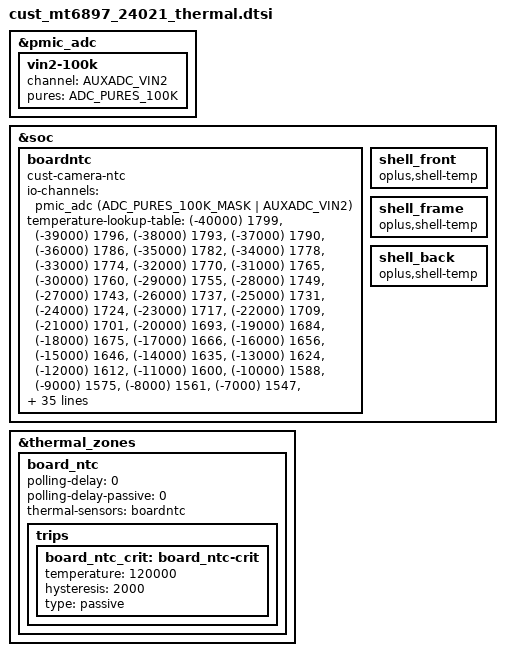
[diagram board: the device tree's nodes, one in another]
// SPDX-License-Identifier: GPL-2.0-only
/*
* Copyright (C) 2022 Oplus. All rights reserved.
*/

#include <dt-bindings/iio/mt635x-auxadc.h>

&pmic_adc {
	vin2-100k {
		channel = <AUXADC_VIN2>;
		pures = <ADC_PURES_100K>;
	};
};

&soc {
	boardntc: boardntc {
		compatible = "cust-camera-ntc";
		#thermal-sensor-cells = <0>;
		io-channels = <&pmic_adc (ADC_PURES_100K_MASK | AUXADC_VIN2)>;
		io-channel-names = "sensor-channel";
		temperature-lookup-table =
			<(-40000) 1799>,
			<(-39000) 1796>,
			<(-38000) 1793>,
			<(-37000) 1790>,
			<(-36000) 1786>,
			<(-35000) 1782>,
			<(-34000) 1778>,
			<(-33000) 1774>,
			<(-32000) 1770>,
			<(-31000) 1765>,
			<(-30000) 1760>,
			<(-29000) 1755>,
			<(-28000) 1749>,
			<(-27000) 1743>,
			<(-26000) 1737>,
			<(-25000) 1731>,
			<(-24000) 1724>,
			<(-23000) 1717>,
			<(-22000) 1709>,
			<(-21000) 1701>,
			<(-20000) 1693>,
			<(-19000) 1684>,
			<(-18000) 1675>,
			<(-17000) 1666>,
			<(-16000) 1656>,
			<(-15000) 1646>,
			<(-14000) 1635>,
			<(-13000) 1624>,
			<(-12000) 1612>,
			<(-11000) 1600>,
			<(-10000) 1588>,
			<(-9000) 1575>,
			<(-8000) 1561>,
			<(-7000) 1547>,
			<(-6000)1533>,
			<(-5000) 1518>,
			<(-4000) 1503>,
			<(-3000) 1487>,
			<(-2000) 1471>,
			<(-1000) 1454>,
			<0 1437>,
			<1000 1420>,
			<2000 1402>,
			<3000 1384>,
			<4000 1365>,
			<5000 1346>,
			<6000 1327>,
			<7000 1307>,
			<8000 1287>,
			<9000 1267>,
			<10000 1246>,
			<11000 1225>,
			<12000 1204>,
			<13000 1183>,
			<14000 1161>,
			<15000 1139>,
			<16000 1118>,
			<17000 1096>,
			<18000 1074>,
			<19000 1052>,
			<20000 1030>,
			<21000 1008>,
			<22000 986>,
			<23000 964>,
			<24000 942>,
			<25000 920>,
			<26000 898>,
			<27000 877>,
			<28000 855>,
			<29000 834>,
			<30000 813>,
			<31000 793>,
			<32000 772>,
			<33000 752>,
			<34000 732>,
			<35000 712>,
			<36000 693>,
			<37000 674>,
			<38000 655>,
			<39000 637>,
			<40000 619>,
			<41000 601>,
			<42000 584>,
			<43000 567>,
			<44000 550>,
			<45000 534>,
			<46000 518>,
			<47000 503>,
			<48000 488>,
			<49000 473>,
			<50000 459>,
			<51000 445>,
			<52000 431>,
			<53000 418>,
			<54000 405>,
			<55000 392>,
			<56000 380>,
			<57000 368>,
			<58000 357>,
			<59000 345>,
			<60000 335>,
			<61000 324>,
			<62000 314>,
			<63000 304>,
			<64000 294>,
			<65000 285>,
			<66000 276>,
			<67000 267>,
			<68000 259>,
			<69000 250>,
			<70000 243>,
			<71000 235>,
			<72000 227>,
			<73000 220>,
			<74000 213>,
			<75000 206>,
			<76000 200>,
			<77000 194>,
			<78000 187>,
			<79000 182>,
			<80000 176>,
			<81000 170>,
			<82000 165>,
			<83000 160>,
			<84000 155>,
			<85000 150>,
			<86000 145>,
			<87000 141>,
			<88000 136>,
			<89000 132>,
			<90000 128>,
			<91000 124>,
			<92000 120>,
			<93000 117>,
			<94000 113>,
			<95000 110>,
			<96000 106>,
			<97000 103>,
			<98000 100>,
			<99000 97>,
			<100000 94>,
			<101000 91>,
			<102000 88>,
			<103000 86>,
			<104000 83>,
			<105000 81>,
			<106000 78>,
			<107000 76>,
			<108000 74>,
			<109000 72>,
			<110000 70>,
			<111000 68>,
			<112000 66>,
			<113000 64>,
			<114000 62>,
			<115000 60>,
			<116000 58>,
			<117000 57>,
			<118000 55>,
			<119000 54>,
			<120000 52>,
			<121000 51>,
			<122000 49>,
			<123000 48>,
			<124000 47>,
			<125000 45>;
	};

	//#ifdef OPLUS_FEATURE_POWER_THERMAL
	shell_front {
		compatible = "oplus,shell-temp";
	};

	shell_frame {
		compatible = "oplus,shell-temp";
	};

	shell_back {
		compatible = "oplus,shell-temp";
	};
//#endif /* OPLUS_FEATURE_POWER_THERMAL */
};


&thermal_zones {
	board_ntc: board_ntc {
		polling-delay = <0>; /* milliseconds */
		polling-delay-passive = <0>; /* milliseconds */
		thermal-sensors = <&boardntc>;
        trips {
			board_ntc_crit: board_ntc-crit {
				temperature = <120000>;
				hysteresis = <2000>;
				type = "passive";
			};
        };
	};
};

